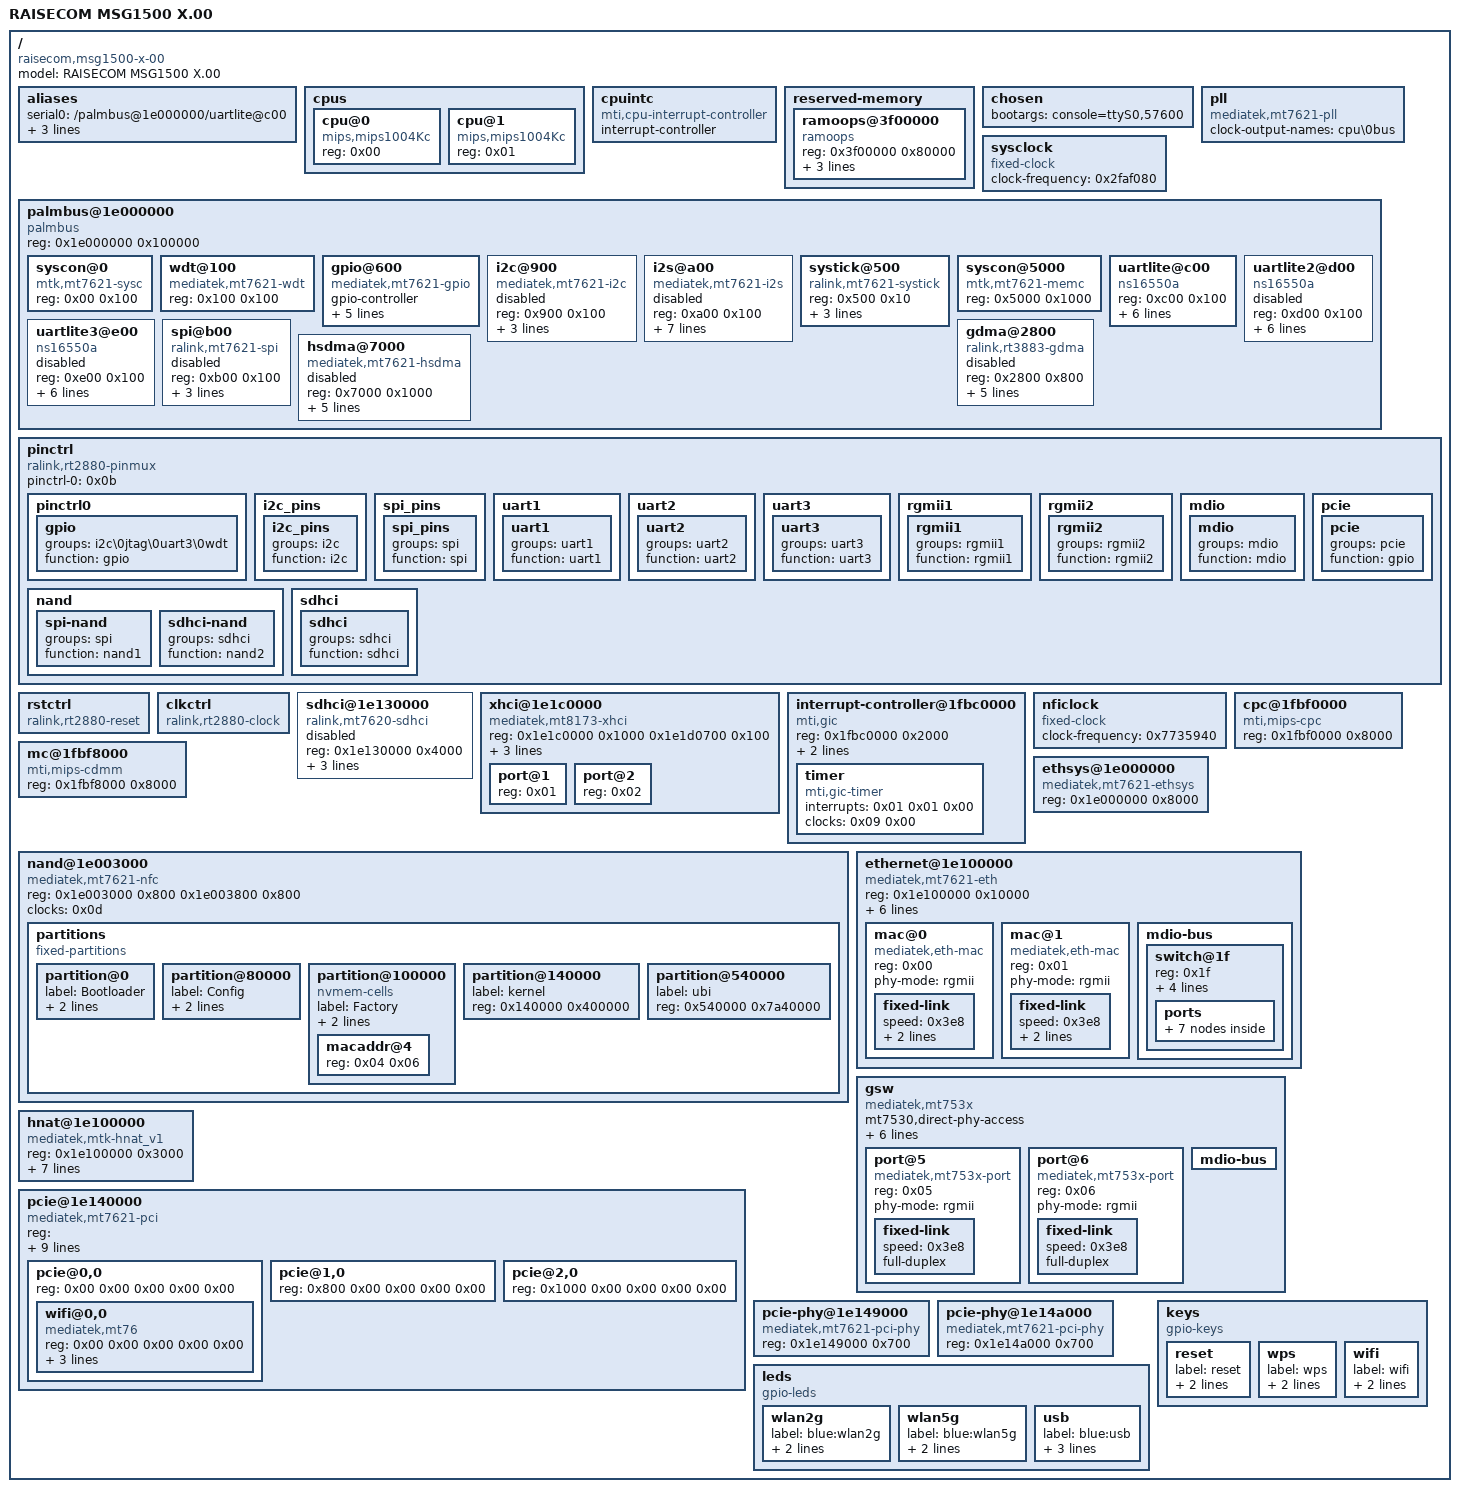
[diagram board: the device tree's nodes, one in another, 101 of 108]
/dts-v1/;

/ {
	#address-cells = <0x01>;
	#size-cells = <0x01>;
	compatible = "raisecom,msg1500-x-00\0mediatek,mt7621-soc";
	model = "RAISECOM MSG1500 X.00";

	aliases {
		serial0 = "/palmbus@1e000000/uartlite@c00";
		led-boot = "/leds/usb";
		led-failsafe = "/leds/usb";
		led-upgrade = "/leds/usb";
	};

	cpus {
		#address-cells = <0x01>;
		#size-cells = <0x00>;

		cpu@0 {
			device_type = "cpu";
			compatible = "mips,mips1004Kc";
			reg = <0x00>;
		};

		cpu@1 {
			device_type = "cpu";
			compatible = "mips,mips1004Kc";
			reg = <0x01>;
		};
	};

	cpuintc {
		#address-cells = <0x00>;
		#interrupt-cells = <0x01>;
		interrupt-controller;
		compatible = "mti,cpu-interrupt-controller";
	};

	reserved-memory {
		#address-cells = <0x01>;
		#size-cells = <0x01>;
		ranges;

		ramoops@3f00000 {
			compatible = "ramoops";
			reg = <0x3f00000 0x80000>;
			record-size = <0x10000>;
			console-size = <0x10000>;
			ftrace-size = <0x20000>;
		};
	};

	chosen {
		bootargs = "console=ttyS0,57600";
	};

	pll {
		compatible = "mediatek,mt7621-pll\0syscon";
		#clock-cells = <0x01>;
		clock-output-names = "cpu\0bus";
		phandle = <0x09>;
	};

	sysclock {
		#clock-cells = <0x00>;
		compatible = "fixed-clock";
		clock-frequency = <0x2faf080>;
		phandle = <0x03>;
	};

	palmbus@1e000000 {
		compatible = "palmbus";
		reg = <0x1e000000 0x100000>;
		ranges = <0x00 0x1e000000 0xfffff>;
		#address-cells = <0x01>;
		#size-cells = <0x01>;

		syscon@0 {
			compatible = "mtk,mt7621-sysc\0syscon";
			reg = <0x00 0x100>;
		};

		wdt@100 {
			compatible = "mediatek,mt7621-wdt";
			reg = <0x100 0x100>;
		};

		gpio@600 {
			#gpio-cells = <0x02>;
			#interrupt-cells = <0x02>;
			compatible = "mediatek,mt7621-gpio";
			gpio-controller;
			gpio-ranges = <0x01 0x00 0x00 0x5f>;
			interrupt-controller;
			reg = <0x600 0x100>;
			interrupt-parent = <0x02>;
			interrupts = <0x00 0x0c 0x04>;
			phandle = <0x18>;
		};

		i2c@900 {
			compatible = "mediatek,mt7621-i2c";
			reg = <0x900 0x100>;
			clocks = <0x03>;
			resets = <0x04 0x10>;
			reset-names = "i2c";
			#address-cells = <0x01>;
			#size-cells = <0x00>;
			status = "disabled";
			pinctrl-names = "default";
			pinctrl-0 = <0x05>;
		};

		i2s@a00 {
			compatible = "mediatek,mt7621-i2s";
			reg = <0xa00 0x100>;
			clocks = <0x03>;
			resets = <0x04 0x11>;
			reset-names = "i2s";
			interrupt-parent = <0x02>;
			interrupts = <0x00 0x10 0x04>;
			txdma-req = <0x02>;
			rxdma-req = <0x03>;
			dmas = <0x06 0x04 0x06 0x06>;
			dma-names = "tx\0rx";
			status = "disabled";
		};

		systick@500 {
			compatible = "ralink,mt7621-systick\0ralink,cevt-systick";
			reg = <0x500 0x10>;
			resets = <0x04 0x1c>;
			reset-names = "intc";
			interrupt-parent = <0x02>;
			interrupts = <0x00 0x05 0x04>;
		};

		syscon@5000 {
			compatible = "mtk,mt7621-memc\0syscon";
			reg = <0x5000 0x1000>;
		};

		uartlite@c00 {
			compatible = "ns16550a";
			reg = <0xc00 0x100>;
			clock-frequency = <0x2faf080>;
			interrupt-parent = <0x02>;
			interrupts = <0x00 0x1a 0x04>;
			reg-shift = <0x02>;
			reg-io-width = <0x04>;
			no-loopback-test;
		};

		uartlite2@d00 {
			compatible = "ns16550a";
			reg = <0xd00 0x100>;
			clock-frequency = <0x2faf080>;
			interrupt-parent = <0x02>;
			interrupts = <0x00 0x1b 0x04>;
			reg-shift = <0x02>;
			reg-io-width = <0x04>;
			pinctrl-names = "default";
			pinctrl-0 = <0x07>;
			status = "disabled";
		};

		uartlite3@e00 {
			compatible = "ns16550a";
			reg = <0xe00 0x100>;
			clock-frequency = <0x2faf080>;
			interrupt-parent = <0x02>;
			interrupts = <0x00 0x1c 0x04>;
			reg-shift = <0x02>;
			reg-io-width = <0x04>;
			pinctrl-names = "default";
			pinctrl-0 = <0x08>;
			status = "disabled";
		};

		spi@b00 {
			status = "disabled";
			compatible = "ralink,mt7621-spi";
			reg = <0xb00 0x100>;
			clocks = <0x09 0x01>;
			resets = <0x04 0x12>;
			reset-names = "spi";
			#address-cells = <0x01>;
			#size-cells = <0x00>;
			pinctrl-names = "default";
			pinctrl-0 = <0x0a>;
		};

		gdma@2800 {
			compatible = "ralink,rt3883-gdma";
			reg = <0x2800 0x800>;
			resets = <0x04 0x0e>;
			reset-names = "dma";
			interrupt-parent = <0x02>;
			interrupts = <0x00 0x0d 0x04>;
			#dma-cells = <0x01>;
			#dma-channels = <0x10>;
			#dma-requests = <0x10>;
			status = "disabled";
			phandle = <0x06>;
		};

		hsdma@7000 {
			compatible = "mediatek,mt7621-hsdma";
			reg = <0x7000 0x1000>;
			resets = <0x04 0x05>;
			reset-names = "hsdma";
			interrupt-parent = <0x02>;
			interrupts = <0x00 0x0b 0x04>;
			#dma-cells = <0x01>;
			#dma-channels = <0x01>;
			#dma-requests = <0x01>;
			status = "disabled";
		};
	};

	pinctrl {
		compatible = "ralink,rt2880-pinmux";
		pinctrl-names = "default";
		pinctrl-0 = <0x0b>;
		phandle = <0x01>;

		pinctrl0 {
			phandle = <0x0b>;

			gpio {
				groups = "i2c\0jtag\0uart3\0wdt";
				function = "gpio";
			};
		};

		i2c_pins {
			phandle = <0x05>;

			i2c_pins {
				groups = "i2c";
				function = "i2c";
			};
		};

		spi_pins {
			phandle = <0x0a>;

			spi_pins {
				groups = "spi";
				function = "spi";
			};
		};

		uart1 {

			uart1 {
				groups = "uart1";
				function = "uart1";
			};
		};

		uart2 {
			phandle = <0x07>;

			uart2 {
				groups = "uart2";
				function = "uart2";
			};
		};

		uart3 {
			phandle = <0x08>;

			uart3 {
				groups = "uart3";
				function = "uart3";
			};
		};

		rgmii1 {
			phandle = <0x10>;

			rgmii1 {
				groups = "rgmii1";
				function = "rgmii1";
			};
		};

		rgmii2 {
			phandle = <0x11>;

			rgmii2 {
				groups = "rgmii2";
				function = "rgmii2";
			};
		};

		mdio {
			phandle = <0x0f>;

			mdio {
				groups = "mdio";
				function = "mdio";
			};
		};

		pcie {
			phandle = <0x14>;

			pcie {
				groups = "pcie";
				function = "gpio";
			};
		};

		nand {

			spi-nand {
				groups = "spi";
				function = "nand1";
			};

			sdhci-nand {
				groups = "sdhci";
				function = "nand2";
			};
		};

		sdhci {
			phandle = <0x0c>;

			sdhci {
				groups = "sdhci";
				function = "sdhci";
			};
		};
	};

	rstctrl {
		compatible = "ralink,rt2880-reset";
		#reset-cells = <0x01>;
		phandle = <0x04>;
	};

	clkctrl {
		compatible = "ralink,rt2880-clock";
		#clock-cells = <0x01>;
		phandle = <0x15>;
	};

	sdhci@1e130000 {
		status = "disabled";
		compatible = "ralink,mt7620-sdhci";
		reg = <0x1e130000 0x4000>;
		interrupt-parent = <0x02>;
		interrupts = <0x00 0x14 0x04>;
		pinctrl-names = "default";
		pinctrl-0 = <0x0c>;
	};

	xhci@1e1c0000 {
		#address-cells = <0x01>;
		#size-cells = <0x00>;
		compatible = "mediatek,mt8173-xhci";
		reg = <0x1e1c0000 0x1000 0x1e1d0700 0x100>;
		reg-names = "mac\0ippc";
		clocks = <0x03>;
		clock-names = "sys_ck";
		interrupt-parent = <0x02>;
		interrupts = <0x00 0x16 0x04>;

		port@1 {
			reg = <0x01>;
			#trigger-source-cells = <0x00>;
		};

		port@2 {
			reg = <0x02>;
			#trigger-source-cells = <0x00>;
			phandle = <0x1b>;
		};
	};

	interrupt-controller@1fbc0000 {
		compatible = "mti,gic";
		reg = <0x1fbc0000 0x2000>;
		interrupt-controller;
		#interrupt-cells = <0x03>;
		mti,reserved-cpu-vectors = <0x07>;
		phandle = <0x02>;

		timer {
			compatible = "mti,gic-timer";
			interrupts = <0x01 0x01 0x00>;
			clocks = <0x09 0x00>;
		};
	};

	nficlock {
		#clock-cells = <0x00>;
		compatible = "fixed-clock";
		clock-frequency = <0x7735940>;
		phandle = <0x0d>;
	};

	cpc@1fbf0000 {
		compatible = "mti,mips-cpc";
		reg = <0x1fbf0000 0x8000>;
	};

	mc@1fbf8000 {
		compatible = "mti,mips-cdmm";
		reg = <0x1fbf8000 0x8000>;
	};

	nand@1e003000 {
		status = "okay";
		compatible = "mediatek,mt7621-nfc";
		reg = <0x1e003000 0x800 0x1e003800 0x800>;
		reg-names = "nfi\0ecc";
		clocks = <0x0d>;
		clock-names = "nfi_clk";

		partitions {
			compatible = "fixed-partitions";
			#address-cells = <0x01>;
			#size-cells = <0x01>;

			partition@0 {
				label = "Bootloader";
				reg = <0x00 0x80000>;
				read-only;
			};

			partition@80000 {
				label = "Config";
				reg = <0x80000 0x80000>;
				read-only;
			};

			partition@100000 {
				label = "Factory";
				reg = <0x100000 0x40000>;
				read-only;
				compatible = "nvmem-cells";
				#address-cells = <0x01>;
				#size-cells = <0x01>;
				phandle = <0x19>;

				macaddr@4 {
					reg = <0x04 0x06>;
					phandle = <0x1a>;
				};
			};

			partition@140000 {
				label = "kernel";
				reg = <0x140000 0x400000>;
			};

			partition@540000 {
				label = "ubi";
				reg = <0x540000 0x7a40000>;
			};
		};
	};

	ethsys@1e000000 {
		compatible = "mediatek,mt7621-ethsys\0syscon";
		reg = <0x1e000000 0x8000>;
		phandle = <0x0e>;
	};

	ethernet@1e100000 {
		compatible = "mediatek,mt7621-eth\0syscon";
		reg = <0x1e100000 0x10000>;
		clocks = <0x03>;
		clock-names = "ethif";
		#address-cells = <0x01>;
		#size-cells = <0x01>;
		resets = <0x04 0x06 0x04 0x17>;
		reset-names = "fe\0eth";
		interrupt-parent = <0x02>;
		interrupts = <0x00 0x03 0x04>;
		mediatek,ethsys = <0x0e>;
		pinctrl-names = "default";
		pinctrl-0 = <0x0f 0x10 0x11>;

		mac@0 {
			compatible = "mediatek,eth-mac";
			reg = <0x00>;
			phy-mode = "rgmii";
			phandle = <0x12>;

			fixed-link {
				speed = <0x3e8>;
				full-duplex;
				pause;
			};
		};

		mac@1 {
			compatible = "mediatek,eth-mac";
			reg = <0x01>;
			phy-mode = "rgmii";

			fixed-link {
				speed = <0x3e8>;
				full-duplex;
				pause;
			};
		};

		mdio-bus {
			#address-cells = <0x01>;
			#size-cells = <0x00>;
			phandle = <0x13>;

			switch@1f {
				reg = <0x1f>;
				mediatek,mcm;
				resets = <0x04 0x02>;
				reset-names = "mcm";
				interrupt-controller;
				#interrupt-cells = <0x01>;
				interrupts = <0x00 0x17 0x04>;

				ports {
					#address-cells = <0x01>;
					#size-cells = <0x00>;

					port@0 {
						status = "disabled";
						reg = <0x00>;
						label = "lan0";
					};

					port@1 {
						status = "disabled";
						reg = <0x01>;
						label = "lan1";
					};

					port@2 {
						status = "disabled";
						reg = <0x02>;
						label = "lan2";
					};

					port@3 {
						status = "disabled";
						reg = <0x03>;
						label = "lan3";
					};

					port@4 {
						status = "disabled";
						reg = <0x04>;
						label = "lan4";
					};

					port@6 {
						reg = <0x06>;
						label = "cpu";
						ethernet = <0x12>;
						phy-mode = "rgmii";

						fixed-link {
							speed = <0x3e8>;
							full-duplex;
							pause;
						};
					};
				};
			};
		};
	};

	gsw {
		compatible = "mediatek,mt753x";
		mt7530,direct-phy-access;
		interrupt-parent = <0x02>;
		interrupts = <0x00 0x17 0x04>;
		#address-cells = <0x01>;
		#size-cells = <0x00>;
		mediatek,mdio = <0x13>;
		mediatek,portmap = "llllw";
		mediatek,mcm;
		resets = <0x04 0x02>;
		reset-names = "mcm";

		port@5 {
			compatible = "mediatek,mt753x-port";
			reg = <0x05>;
			phy-mode = "rgmii";

			fixed-link {
				speed = <0x3e8>;
				full-duplex;
			};
		};

		port@6 {
			compatible = "mediatek,mt753x-port";
			reg = <0x06>;
			phy-mode = "rgmii";

			fixed-link {
				speed = <0x3e8>;
				full-duplex;
			};
		};

		mdio-bus {
			#address-cells = <0x01>;
			#size-cells = <0x00>;
		};
	};

	hnat@1e100000 {
		compatible = "mediatek,mtk-hnat_v1";
		reg = <0x1e100000 0x3000>;
		resets = <0x0e 0x00>;
		reset-names = "mtketh";
		status = "okay";
		mtketh-wan = "eth1";
		mtketh-ppd = "eth0";
		mtketh-lan = "eth0";
		ext-devices = "wlan0\0wlan1\0rax0\0ra0\0rai0\0apclii0\0apclix0\0apcli0";
		mtketh-max-gmac = <0x02>;
	};

	pcie@1e140000 {
		compatible = "mediatek,mt7621-pci";
		reg = <0x1e140000 0x100 0x1e142000 0x100 0x1e143000 0x100 0x1e144000 0x100>;
		#address-cells = <0x03>;
		#size-cells = <0x02>;
		pinctrl-names = "default";
		pinctrl-0 = <0x14>;
		device_type = "pci";
		ranges = <0x2000000 0x00 0x00 0x60000000 0x00 0x10000000 0x1000000 0x00 0x00 0x1e160000 0x00 0x10000>;
		status = "okay";
		interrupt-parent = <0x02>;
		interrupts = <0x00 0x04 0x04 0x00 0x18 0x04 0x00 0x19 0x04>;
		resets = <0x04 0x18 0x04 0x19 0x04 0x1a>;
		reset-names = "pcie0\0pcie1\0pcie2";
		clocks = <0x15 0x18 0x15 0x19 0x15 0x1a>;
		clock-names = "pcie0\0pcie1\0pcie2";
		phys = <0x16 0x01 0x17 0x00>;
		phy-names = "pcie-phy0\0pcie-phy2";
		reset-gpios = <0x18 0x13 0x01>;

		pcie@0,0 {
			reg = <0x00 0x00 0x00 0x00 0x00>;
			#address-cells = <0x03>;
			#size-cells = <0x02>;
			device_type = "pci";
			ranges;

			wifi@0,0 {
				compatible = "mediatek,mt76";
				reg = <0x00 0x00 0x00 0x00 0x00>;
				mediatek,mtd-eeprom = <0x19 0x00>;
				nvmem-cells = <0x1a>;
				nvmem-cell-names = "mac-address";
			};
		};

		pcie@1,0 {
			reg = <0x800 0x00 0x00 0x00 0x00>;
			#address-cells = <0x03>;
			#size-cells = <0x02>;
			device_type = "pci";
			ranges;
		};

		pcie@2,0 {
			reg = <0x1000 0x00 0x00 0x00 0x00>;
			#address-cells = <0x03>;
			#size-cells = <0x02>;
			device_type = "pci";
			ranges;
		};
	};

	pcie-phy@1e149000 {
		compatible = "mediatek,mt7621-pci-phy";
		reg = <0x1e149000 0x700>;
		#phy-cells = <0x01>;
		phandle = <0x16>;
	};

	pcie-phy@1e14a000 {
		compatible = "mediatek,mt7621-pci-phy";
		reg = <0x1e14a000 0x700>;
		#phy-cells = <0x01>;
		phandle = <0x17>;
	};

	leds {
		compatible = "gpio-leds";

		wlan2g {
			label = "blue:wlan2g";
			gpios = <0x18 0x04 0x01>;
			linux,default-trigger = "phy0radio";
		};

		wlan5g {
			label = "blue:wlan5g";
			gpios = <0x18 0x03 0x01>;
			linux,default-trigger = "phy1radio";
		};

		usb {
			label = "blue:usb";
			gpios = <0x18 0x0d 0x01>;
			trigger-sources = <0x1b>;
			linux,default-trigger = "usbport";
		};
	};

	keys {
		compatible = "gpio-keys";

		reset {
			label = "reset";
			gpios = <0x18 0x0f 0x01>;
			linux,code = <0x198>;
		};

		wps {
			label = "wps";
			gpios = <0x18 0x12 0x01>;
			linux,code = <0x211>;
		};

		wifi {
			label = "wifi";
			gpios = <0x18 0x07 0x01>;
			linux,code = <0xf7>;
		};
	};
};
